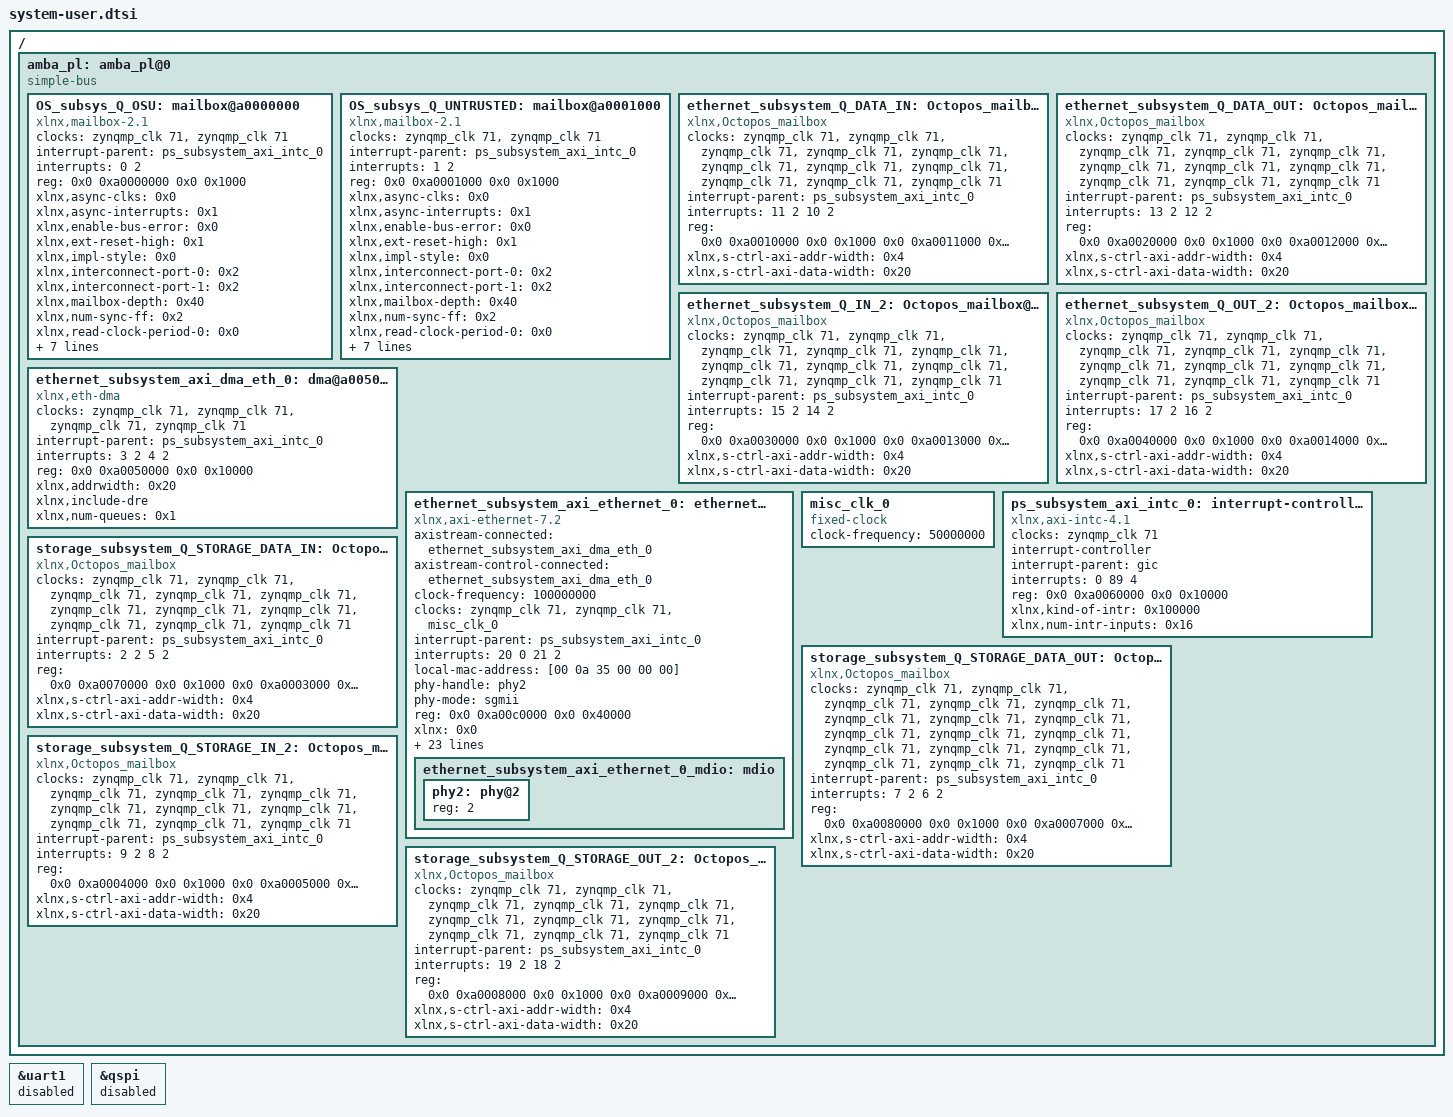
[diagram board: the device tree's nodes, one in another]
/include/ "system-conf.dtsi"
/ {
};

&uart1 {
        status="disabled";
};

&qspi {
        status="disabled";
};

/delete-node/ &amba_pl;

/ {
	amba_pl: amba_pl@0 {
		#address-cells = <2>;
		#size-cells = <2>;
		compatible = "simple-bus";
		ranges ;
		OS_subsys_Q_OSU: mailbox@a0000000 {
			clock-names = "S0_AXI_ACLK", "S1_AXI_ACLK";
			clocks = <&zynqmp_clk 71>, <&zynqmp_clk 71>;
			compatible = "xlnx,mailbox-2.1";
			interrupt-names = "Interrupt_1";
			interrupt-parent = <&ps_subsystem_axi_intc_0>;
			interrupts = <0 2>;
			reg = <0x0 0xa0000000 0x0 0x1000>;
			xlnx,async-clks = <0x0>;
			xlnx,async-interrupts = <0x1>;
			xlnx,enable-bus-error = <0x0>;
			xlnx,ext-reset-high = <0x1>;
			xlnx,impl-style = <0x0>;
			xlnx,interconnect-port-0 = <0x2>;
			xlnx,interconnect-port-1 = <0x2>;
			xlnx,mailbox-depth = <0x40>;
			xlnx,num-sync-ff = <0x2>;
			xlnx,read-clock-period-0 = <0x0>;
			xlnx,read-clock-period-1 = <0x0>;
			xlnx,s0-axi-aclk-freq-mhz = "99.990005";
			xlnx,s0-axi-addr-width = <0x20>;
			xlnx,s0-axi-data-width = <0x20>;
			xlnx,s1-axi-aclk-freq-mhz = "99.990005";
			xlnx,s1-axi-addr-width = <0x20>;
			xlnx,s1-axi-data-width = <0x20>;
		};
		OS_subsys_Q_UNTRUSTED: mailbox@a0001000 {
			clock-names = "S0_AXI_ACLK", "S1_AXI_ACLK";
			clocks = <&zynqmp_clk 71>, <&zynqmp_clk 71>;
			compatible = "xlnx,mailbox-2.1";
			interrupt-names = "Interrupt_1";
			interrupt-parent = <&ps_subsystem_axi_intc_0>;
			interrupts = <1 2>;
			reg = <0x0 0xa0001000 0x0 0x1000>;
			xlnx,async-clks = <0x0>;
			xlnx,async-interrupts = <0x1>;
			xlnx,enable-bus-error = <0x0>;
			xlnx,ext-reset-high = <0x1>;
			xlnx,impl-style = <0x0>;
			xlnx,interconnect-port-0 = <0x2>;
			xlnx,interconnect-port-1 = <0x2>;
			xlnx,mailbox-depth = <0x40>;
			xlnx,num-sync-ff = <0x2>;
			xlnx,read-clock-period-0 = <0x0>;
			xlnx,read-clock-period-1 = <0x0>;
			xlnx,s0-axi-aclk-freq-mhz = "99.990005";
			xlnx,s0-axi-addr-width = <0x20>;
			xlnx,s0-axi-data-width = <0x20>;
			xlnx,s1-axi-aclk-freq-mhz = "99.990005";
			xlnx,s1-axi-addr-width = <0x20>;
			xlnx,s1-axi-data-width = <0x20>;
		};
		ethernet_subsystem_Q_DATA_IN: Octopos_mailbox@a0010000 {
			clock-names = "S_CLK", "s_ctrl0_axi_aclk", "s_ctrl1_axi_aclk", "s_ctrl2_axi_aclk", "s_ctrl3_axi_aclk", "s_ctrl_fixed_axi_aclk", "S0_data0_AXI_ACLK", "S0_data1_AXI_ACLK", "S0_data2_AXI_ACLK", "S0_data3_AXI_ACLK", "S1_data_fixed_AXI_ACLK";
			clocks = <&zynqmp_clk 71>, <&zynqmp_clk 71>, <&zynqmp_clk 71>, <&zynqmp_clk 71>, <&zynqmp_clk 71>, <&zynqmp_clk 71>, <&zynqmp_clk 71>, <&zynqmp_clk 71>, <&zynqmp_clk 71>, <&zynqmp_clk 71>, <&zynqmp_clk 71>;
			compatible = "xlnx,Octopos_mailbox";
			interrupt-names = "Interrupt_ctrl3", "Interrupt_3";
			interrupt-parent = <&ps_subsystem_axi_intc_0>;
			interrupts = <11 2 10 2>;
			reg = <0x0 0xa0010000 0x0 0x1000 0x0 0xa0011000 0x0 0x1000>;
			xlnx,s-ctrl-axi-addr-width = <0x4>;
			xlnx,s-ctrl-axi-data-width = <0x20>;
		};
		ethernet_subsystem_Q_DATA_OUT: Octopos_mailbox@a0020000 {
			clock-names = "S_CLK", "s_ctrl0_axi_aclk", "s_ctrl1_axi_aclk", "s_ctrl2_axi_aclk", "s_ctrl3_axi_aclk", "s_ctrl_fixed_axi_aclk", "S0_data0_AXI_ACLK", "S0_data1_AXI_ACLK", "S0_data2_AXI_ACLK", "S0_data3_AXI_ACLK", "S1_data_fixed_AXI_ACLK";
			clocks = <&zynqmp_clk 71>, <&zynqmp_clk 71>, <&zynqmp_clk 71>, <&zynqmp_clk 71>, <&zynqmp_clk 71>, <&zynqmp_clk 71>, <&zynqmp_clk 71>, <&zynqmp_clk 71>, <&zynqmp_clk 71>, <&zynqmp_clk 71>, <&zynqmp_clk 71>;
			compatible = "xlnx,Octopos_mailbox";
			interrupt-names = "Interrupt_ctrl3", "Interrupt_3";
			interrupt-parent = <&ps_subsystem_axi_intc_0>;
			interrupts = <13 2 12 2>;
			reg = <0x0 0xa0020000 0x0 0x1000 0x0 0xa0012000 0x0 0x1000>;
			xlnx,s-ctrl-axi-addr-width = <0x4>;
			xlnx,s-ctrl-axi-data-width = <0x20>;
		};
		ethernet_subsystem_Q_IN_2: Octopos_mailbox@a0030000 {
			clock-names = "S_CLK", "s_ctrl0_axi_aclk", "s_ctrl1_axi_aclk", "s_ctrl2_axi_aclk", "s_ctrl3_axi_aclk", "s_ctrl_fixed_axi_aclk", "S0_data0_AXI_ACLK", "S0_data1_AXI_ACLK", "S0_data2_AXI_ACLK", "S0_data3_AXI_ACLK", "S1_data_fixed_AXI_ACLK";
			clocks = <&zynqmp_clk 71>, <&zynqmp_clk 71>, <&zynqmp_clk 71>, <&zynqmp_clk 71>, <&zynqmp_clk 71>, <&zynqmp_clk 71>, <&zynqmp_clk 71>, <&zynqmp_clk 71>, <&zynqmp_clk 71>, <&zynqmp_clk 71>, <&zynqmp_clk 71>;
			compatible = "xlnx,Octopos_mailbox";
			interrupt-names = "Interrupt_ctrl3", "Interrupt_3";
			interrupt-parent = <&ps_subsystem_axi_intc_0>;
			interrupts = <15 2 14 2>;
			reg = <0x0 0xa0030000 0x0 0x1000 0x0 0xa0013000 0x0 0x1000>;
			xlnx,s-ctrl-axi-addr-width = <0x4>;
			xlnx,s-ctrl-axi-data-width = <0x20>;
		};
		ethernet_subsystem_Q_OUT_2: Octopos_mailbox@a0040000 {
			clock-names = "S_CLK", "s_ctrl0_axi_aclk", "s_ctrl1_axi_aclk", "s_ctrl2_axi_aclk", "s_ctrl3_axi_aclk", "s_ctrl_fixed_axi_aclk", "S0_data0_AXI_ACLK", "S0_data1_AXI_ACLK", "S0_data2_AXI_ACLK", "S0_data3_AXI_ACLK", "S1_data_fixed_AXI_ACLK";
			clocks = <&zynqmp_clk 71>, <&zynqmp_clk 71>, <&zynqmp_clk 71>, <&zynqmp_clk 71>, <&zynqmp_clk 71>, <&zynqmp_clk 71>, <&zynqmp_clk 71>, <&zynqmp_clk 71>, <&zynqmp_clk 71>, <&zynqmp_clk 71>, <&zynqmp_clk 71>;
			compatible = "xlnx,Octopos_mailbox";
			interrupt-names = "Interrupt_ctrl3", "Interrupt_3";
			interrupt-parent = <&ps_subsystem_axi_intc_0>;
			interrupts = <17 2 16 2>;
			reg = <0x0 0xa0040000 0x0 0x1000 0x0 0xa0014000 0x0 0x1000>;
			xlnx,s-ctrl-axi-addr-width = <0x4>;
			xlnx,s-ctrl-axi-data-width = <0x20>;
		};
		ethernet_subsystem_axi_dma_eth_0: dma@a0050000 {
			#dma-cells = <1>;
			clock-names = "s_axi_lite_aclk", "m_axi_sg_aclk", "m_axi_mm2s_aclk", "m_axi_s2mm_aclk";
			clocks = <&zynqmp_clk 71>, <&zynqmp_clk 71>, <&zynqmp_clk 71>, <&zynqmp_clk 71>;
			compatible = "xlnx,eth-dma";
			interrupt-names = "mm2s_introut", "s2mm_introut";
			interrupt-parent = <&ps_subsystem_axi_intc_0>;
			interrupts = <3 2 4 2>;
			reg = <0x0 0xa0050000 0x0 0x10000>;
			xlnx,addrwidth = /bits/ 8 <0x20>;
			xlnx,include-dre ;
			xlnx,num-queues = /bits/ 16 <0x1>;
		};
		ethernet_subsystem_axi_ethernet_0: ethernet@a00c0000 {
			axistream-connected = <&ethernet_subsystem_axi_dma_eth_0>;
			axistream-control-connected = <&ethernet_subsystem_axi_dma_eth_0>;
			clock-frequency = <100000000>;
			clock-names = "s_axi_lite_clk", "axis_clk", "ref_clk";
			clocks = <&zynqmp_clk 71>, <&zynqmp_clk 71>, <&misc_clk_0>;
			compatible = "xlnx,axi-ethernet-7.2", "xlnx,axi-ethernet-1.00.a";
			device_type = "network";
			interrupt-names = "mac_irq", "interrupt";
			interrupt-parent = <&ps_subsystem_axi_intc_0>;
			interrupts = <20 0 21 2>;
			local-mac-address = [00 0a 35 00 00 00];
			phy-handle = <&phy2>;
			phy-mode = "sgmii";
			reg = <0x0 0xa00c0000 0x0 0x40000>;
			xlnx = <0x0>;
			xlnx,axiliteclkrate = <0x0>;
			xlnx,axisclkrate = <0x0>;
			xlnx,clockselection = <0x0>;
			xlnx,enableasyncsgmii = <0x0>;
			xlnx,gt-type = <0x0>;
			xlnx,gtinex = <0x0>;
			xlnx,gtlocation = <0x0>;
			xlnx,gtrefclksrc = <0x0>;
			xlnx,include-dre ;
			xlnx,instantiatebitslice0 = <0x0>;
			xlnx,phy-type = <0x5>;
			xlnx,phyaddr = <0x2>;
			xlnx,phyrst-board-interface-dummy-port = <0x0>;
			xlnx,rable = <0x0>;
			xlnx,rxcsum = <0x2>;
			xlnx,rxlane0-placement = <0x0>;
			xlnx,rxlane1-placement = <0x0>;
			xlnx,rxmem = <0x2000>;
			xlnx,rxnibblebitslice0used = <0x0>;
			xlnx,tx-in-upper-nibble = <0x1>;
			xlnx,txcsum = <0x2>;
			xlnx,txlane0-placement = <0x0>;
			xlnx,txlane1-placement = <0x0>;
			ethernet_subsystem_axi_ethernet_0_mdio: mdio {
				#address-cells = <1>;
				#size-cells = <0>;
				phy2: phy@2 {
					device_type = "ethernet-phy";
					reg = <2>;
				};
			};
		};
		misc_clk_0: misc_clk_0 {
			#clock-cells = <0>;
			clock-frequency = <50000000>;
			compatible = "fixed-clock";
		};
                ps_subsystem_axi_intc_0: interrupt-controller@a0060000 {
                        #interrupt-cells = <2>;
                        clock-names = "s_axi_aclk";
                        clocks = <&zynqmp_clk 71>;
                        compatible = "xlnx,axi-intc-4.1", "xlnx,xps-intc-1.00.a";
                        interrupt-controller ;
                        interrupt-names = "irq";
                        interrupt-parent = <&gic>;
                        interrupts = <0 89 4>;
                        reg = <0x0 0xa0060000 0x0 0x10000>;
                        xlnx,kind-of-intr = <0x100000>;
                        xlnx,num-intr-inputs = <0x16>;
                };
		storage_subsystem_Q_STORAGE_DATA_IN: Octopos_mailbox@a0070000 {
			clock-names = "S_CLK", "s_ctrl0_axi_aclk", "s_ctrl1_axi_aclk", "s_ctrl2_axi_aclk", "s_ctrl3_axi_aclk", "s_ctrl_fixed_axi_aclk", "S0_data0_AXI_ACLK", "S0_data1_AXI_ACLK", "S0_data2_AXI_ACLK", "S0_data3_AXI_ACLK", "S1_data_fixed_AXI_ACLK";
			clocks = <&zynqmp_clk 71>, <&zynqmp_clk 71>, <&zynqmp_clk 71>, <&zynqmp_clk 71>, <&zynqmp_clk 71>, <&zynqmp_clk 71>, <&zynqmp_clk 71>, <&zynqmp_clk 71>, <&zynqmp_clk 71>, <&zynqmp_clk 71>, <&zynqmp_clk 71>;
			compatible = "xlnx,Octopos_mailbox";
			interrupt-names = "Interrupt_ctrl3", "Interrupt_3";
			interrupt-parent = <&ps_subsystem_axi_intc_0>;
			interrupts = <2 2 5 2>;
			reg = <0x0 0xa0070000 0x0 0x1000 0x0 0xa0003000 0x0 0x1000>;
			xlnx,s-ctrl-axi-addr-width = <0x4>;
			xlnx,s-ctrl-axi-data-width = <0x20>;
		};
		storage_subsystem_Q_STORAGE_DATA_OUT: Octopos_mailbox@a0080000 {
			clock-names = "S_CLK", "s_ctrl0_axi_aclk", "s_ctrl1_axi_aclk", "s_ctrl2_axi_aclk", "s_ctrl3_axi_aclk", "s_ctrl4_axi_aclk", "s_ctrl5_axi_aclk", "s_ctrl6_axi_aclk", "s_ctrl_fixed_axi_aclk", "S0_data0_AXI_ACLK", "S0_data1_AXI_ACLK", "S0_data2_AXI_ACLK", "S0_data3_AXI_ACLK", "S0_data4_AXI_ACLK", "S0_data5_AXI_ACLK", "S0_data6_AXI_ACLK", "S1_data_fixed_AXI_ACLK";
			clocks = <&zynqmp_clk 71>, <&zynqmp_clk 71>, <&zynqmp_clk 71>, <&zynqmp_clk 71>, <&zynqmp_clk 71>, <&zynqmp_clk 71>, <&zynqmp_clk 71>, <&zynqmp_clk 71>, <&zynqmp_clk 71>, <&zynqmp_clk 71>, <&zynqmp_clk 71>, <&zynqmp_clk 71>, <&zynqmp_clk 71>, <&zynqmp_clk 71>, <&zynqmp_clk 71>, <&zynqmp_clk 71>, <&zynqmp_clk 71>;
			compatible = "xlnx,Octopos_mailbox";
			interrupt-names = "Interrupt_ctrl3", "Interrupt_3";
			interrupt-parent = <&ps_subsystem_axi_intc_0>;
			interrupts = <7 2 6 2>;
			reg = <0x0 0xa0080000 0x0 0x1000 0x0 0xa0007000 0x0 0x1000>;
			xlnx,s-ctrl-axi-addr-width = <0x4>;
			xlnx,s-ctrl-axi-data-width = <0x20>;
		};
		storage_subsystem_Q_STORAGE_IN_2: Octopos_mailbox@a0004000 {
			clock-names = "S_CLK", "s_ctrl0_axi_aclk", "s_ctrl1_axi_aclk", "s_ctrl2_axi_aclk", "s_ctrl3_axi_aclk", "s_ctrl_fixed_axi_aclk", "S0_data0_AXI_ACLK", "S0_data1_AXI_ACLK", "S0_data2_AXI_ACLK", "S0_data3_AXI_ACLK", "S1_data_fixed_AXI_ACLK";
			clocks = <&zynqmp_clk 71>, <&zynqmp_clk 71>, <&zynqmp_clk 71>, <&zynqmp_clk 71>, <&zynqmp_clk 71>, <&zynqmp_clk 71>, <&zynqmp_clk 71>, <&zynqmp_clk 71>, <&zynqmp_clk 71>, <&zynqmp_clk 71>, <&zynqmp_clk 71>;
			compatible = "xlnx,Octopos_mailbox";
			interrupt-names = "Interrupt_ctrl3", "Interrupt_3";
			interrupt-parent = <&ps_subsystem_axi_intc_0>;
			interrupts = <9 2 8 2>;
			reg = <0x0 0xa0004000 0x0 0x1000 0x0 0xa0005000 0x0 0x1000>;
			xlnx,s-ctrl-axi-addr-width = <0x4>;
			xlnx,s-ctrl-axi-data-width = <0x20>;
		};
		storage_subsystem_Q_STORAGE_OUT_2: Octopos_mailbox@a0008000 {
			clock-names = "S_CLK", "s_ctrl0_axi_aclk", "s_ctrl1_axi_aclk", "s_ctrl2_axi_aclk", "s_ctrl3_axi_aclk", "s_ctrl_fixed_axi_aclk", "S0_data0_AXI_ACLK", "S0_data1_AXI_ACLK", "S0_data2_AXI_ACLK", "S0_data3_AXI_ACLK", "S1_data_fixed_AXI_ACLK";
			clocks = <&zynqmp_clk 71>, <&zynqmp_clk 71>, <&zynqmp_clk 71>, <&zynqmp_clk 71>, <&zynqmp_clk 71>, <&zynqmp_clk 71>, <&zynqmp_clk 71>, <&zynqmp_clk 71>, <&zynqmp_clk 71>, <&zynqmp_clk 71>, <&zynqmp_clk 71>;
			compatible = "xlnx,Octopos_mailbox";
			interrupt-names = "Interrupt_ctrl3", "Interrupt_3";
			interrupt-parent = <&ps_subsystem_axi_intc_0>;
			interrupts = <19 2 18 2>;
			reg = <0x0 0xa0008000 0x0 0x1000 0x0 0xa0009000 0x0 0x1000>;
			xlnx,s-ctrl-axi-addr-width = <0x4>;
			xlnx,s-ctrl-axi-data-width = <0x20>;
		};
	};
};
